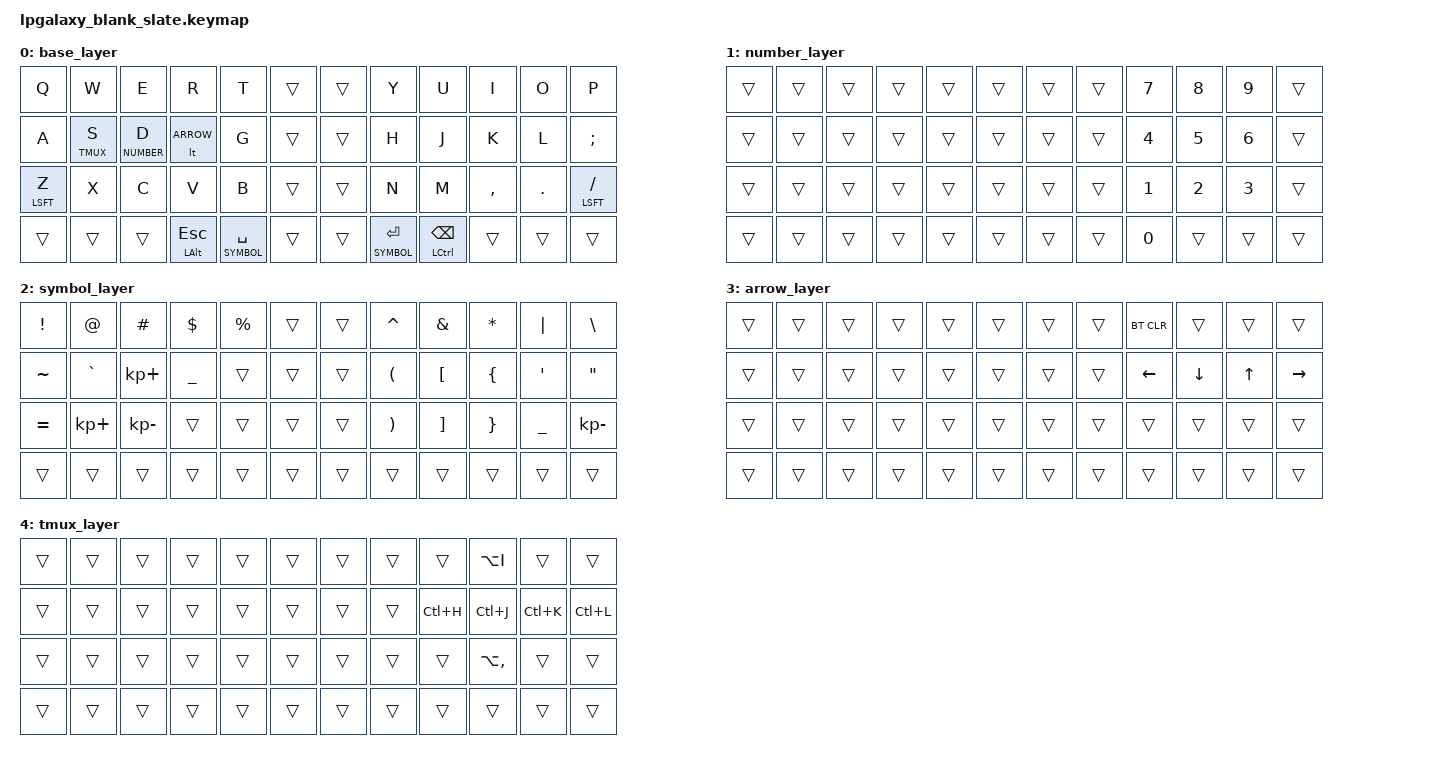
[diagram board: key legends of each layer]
/*
 * Copyright (c) 2022 Pete Johanson
 *
 * SPDX-License-Identifier: MIT
 */

#include <behaviors.dtsi>
#include <dt-bindings/zmk/keys.h>
#include <dt-bindings/zmk/bt.h>
#include <dt-bindings/zmk/outputs.h>

#define BASE 0
#define NUMBER 1
#define SYMBOL 2
#define ARROW 3
#define TMUX 4


// Using layer taps on thumbs, having quick tap as well helps w/ repeating space/backspace
&lt { quick_tap_ms = <200>; };

#define BT(n) BT_SEL n

/ {
    chosen {
       zmk,matrix_transform =
#ifdef TBLE_DUAL_2U
                       &dual_2u_transform;
#elif defined(TBLE_MIT)
                       &mit_transform;
#else
                       &ortho_transform;
#endif
    };


    combos {
        compatible = "zmk,combos";
        combo_del {
            timeout-ms = <50>;
            key-positions = <20 21>;
            bindings = <&kp BSPC>;
        };
        combo_tab {
            timeout-ms = <50>;
            key-positions = <21 22>;
            bindings = <&kp TAB>;
        };
        
         combo_alt {
            timeout-ms = <50>;
            key-positions = <32 33>;
            bindings = <&kp LGUI>;
        };
        
    };

    keymap {
        compatible = "zmk,keymap";

        base_layer {
            bindings = <
 &kp Q      &kp W      &kp E        &kp R      &kp T      &trans  &trans  &kp Y      &kp U      &kp I      &kp O      &kp P 
 &kp A      &lt TMUX S &lt NUMBER D &lt ARROW  &kp G      &trans  &trans  &kp H      &kp J      &kp K      &kp L      &kp SEMI
 &mt LSFT Z &kp X      &kp C        &kp V      &kp B      &trans  &trans  &kp N      &kp M      &kp COMMA  &kp DOT    &mt LSFT SLASH
 &trans     &trans     &trans       &mt LALT ESC &lt SYMBOL SPACE &trans  &trans  &lt SYMBOL ENTER &mt LCTRL BSPC &trans     &trans     &trans
            >;
        };

        number_layer {
            bindings = <
 &trans     &trans     &trans     &trans     &trans     &trans  &trans      &trans     &kp N7     &kp N8     &kp N9     &trans
 &trans     &trans     &trans     &trans     &trans     &trans  &trans      &trans     &kp N4     &kp N5     &kp N6     &trans
 &trans     &trans     &trans     &trans     &trans     &trans  &trans      &trans     &kp N1     &kp N2     &kp N3     &trans
 &trans     &trans     &trans     &trans     &trans     &trans  &trans      &trans     &kp N0     &trans     &trans     &trans
            >;
        };

        symbol_layer {
            bindings = <
      &kp EXCL      &kp AT         &kp HASH       &kp DOLLAR    &kp PERCENT    &trans     &trans     &kp CARET   &kp AMPERSAND &kp ASTERISK  &kp PIPE     &kp BACKSLASH
      &kp TILDE     &kp GRAVE      &kp KP_PLUS    &kp UNDER     &trans         &trans     &trans     &kp LPAR     &kp LBKT       &kp LBRC      &kp SQT      &kp DQT  
      &kp EQUAL     &kp KP_PLUS    &kp KP_MINUS   &trans         &trans         &trans     &trans     &kp RPAR     &kp RBKT       &kp RBRC      &kp UNDER    &kp KP_MINUS  
      &trans        &trans         &trans         &trans         &trans         &trans     &trans     &trans       &trans         &trans        &trans       &trans
            >;
        };


        arrow_layer {
            bindings = <
 &trans     &trans     &trans     &trans     &trans     &trans  &trans  &trans     &bt BT_CLR  &trans     &trans     &trans
 &trans     &trans     &trans     &trans     &trans     &trans  &trans  &trans     &kp LEFT  &kp DOWN    &kp UP  &kp RIGHT  
 &trans     &trans     &trans     &trans     &trans     &trans  &trans  &trans     &trans     &trans     &trans     &trans
 &trans     &trans     &trans     &trans     &trans     &trans  &trans  &trans     &trans     &trans     &trans     &trans
            >;
        };

        tmux_layer {
            bindings = <
 &trans     &trans     &trans     &trans     &trans     &trans  &trans  &trans     &trans     &kp LA(I)     &trans     &trans
 &trans     &trans     &trans     &trans     &trans     &trans  &trans  &trans   &kp LC(H)    &kp LC(J)      &kp LC(K)    &kp LC(L)
 &trans     &trans     &trans     &trans     &trans     &trans  &trans  &trans     &trans     &kp LA(COMMA)     &trans     &trans
 &trans     &trans     &trans     &trans     &trans     &trans  &trans  &trans     &trans     &trans           &trans     &trans
            >;
        };

    };
};

